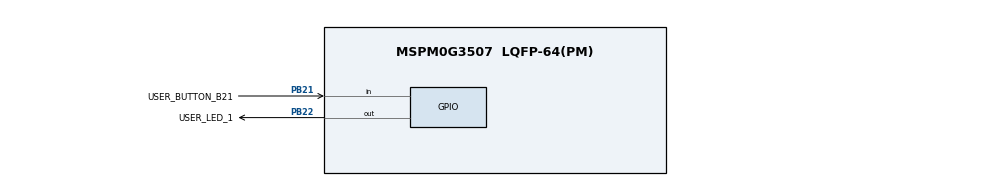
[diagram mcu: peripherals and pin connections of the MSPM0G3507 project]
//@cliArgs --device "MSPM0G350X" --package "LQFP-64(PM)" --part "Default"
//@v2CliArgs --device "MSPM0G3507" --package "LQFP-64(PM)"
// Target hardware: LCKFB Tianmengxing MSPM0G3507 (64-pin)
// @cliArgs --rtos nortos

/**
 * Import the modules used in this configuration.
 */
const SYSCTL = scripting.addModule("/ti/driverlib/SYSCTL");
const GPIO = scripting.addModule("/ti/driverlib/GPIO", {}, false);
const GPIO1 = GPIO.addInstance();
const GPIO2 = GPIO.addInstance();

/**
 * Write custom configuration values to the imported modules.
 */

GPIO1.$name = "GPIO_LEDS";
GPIO1.associatedPins[0].$name = "USER_LED_1";
GPIO1.associatedPins[0].initialValue = "CLEARED";
GPIO1.associatedPins[0].pin.$assign = "PB22";

GPIO2.$name = "GPIO_BUTTONS";
GPIO2.associatedPins[0].$name = "USER_BUTTON_B21";
GPIO2.associatedPins[0].direction = "INPUT";
GPIO2.associatedPins[0].internalResistor = "PULL_UP";
GPIO2.associatedPins[0].pin.$assign = "PB21";

const Board = scripting.addModule("/ti/driverlib/Board", {}, false);

SYSCTL.forceDefaultClkConfig = true;
